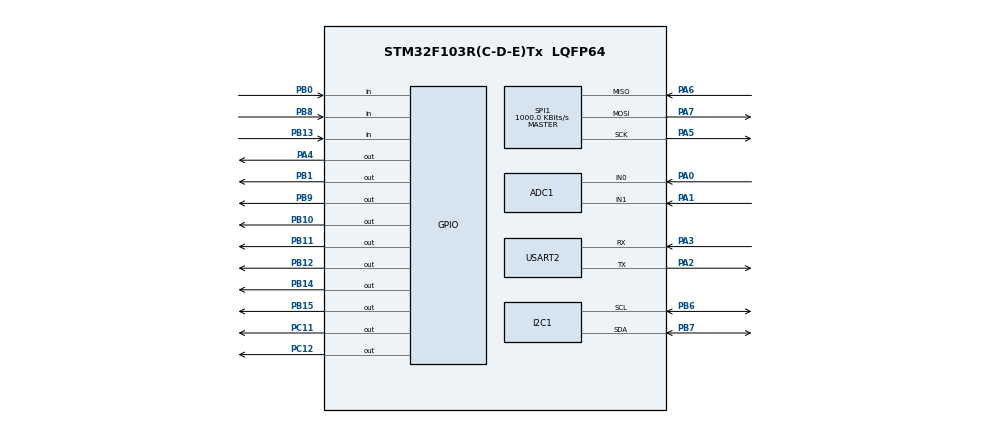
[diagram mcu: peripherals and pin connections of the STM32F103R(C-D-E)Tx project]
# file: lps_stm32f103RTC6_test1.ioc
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ADC1.Channel-0\#ChannelRegularConversion=ADC_CHANNEL_0
ADC1.NbrOfConversionFlag=1
ADC1.Rank-0\#ChannelRegularConversion=1
ADC1.SamplingTime-0\#ChannelRegularConversion=ADC_SAMPLETIME_1CYCLE_5
ADC1.master=1
Mcu.Family=STM32F1
Mcu.Name=STM32F103R(C-D-E)Tx
Mcu.Package=LQFP64
NVIC.PriorityGroup=NVIC_PRIORITYGROUP_4
PA0-WKUP.Signal=ADCx_IN0
PA1.Signal=ADCx_IN1
PA2.Mode=Asynchronous
PA2.Signal=USART2_TX
PA3.Mode=Asynchronous
PA3.Signal=USART2_RX
PA4.Signal=GPIO_Output
PA5.Mode=Full_Duplex_Master
PA5.Signal=SPI1_SCK
PA6.Mode=Full_Duplex_Master
PA6.Signal=SPI1_MISO
PA7.Mode=Full_Duplex_Master
PA7.Signal=SPI1_MOSI
PB0.Signal=GPIO_Input
PB1.Signal=GPIO_Output
PB10.Signal=GPIO_Output
PB11.Signal=GPIO_Output
PB12.Signal=GPIO_Output
PB13.Signal=GPIO_Input
PB14.Signal=GPIO_Output
PB15.Signal=GPIO_Output
PB6.Mode=I2C
PB6.Signal=I2C1_SCL
PB7.Mode=I2C
PB7.Signal=I2C1_SDA
PB8.Signal=GPIO_Input
PB9.Signal=GPIO_Output
PC11.Signal=GPIO_Output
PC12.Signal=GPIO_Output
ProjectManager.HeapSize=0x200
ProjectManager.StackSize=0x400
ProjectManager.TargetToolchain=STM32CubeIDE
RCC.APB1Freq_Value=8000000
RCC.APB2Freq_Value=8000000
SH.ADCx_IN0.0=ADC1_IN0,IN0
SH.ADCx_IN1.0=ADC1_IN1,IN1
SPI1.BaudRatePrescaler=SPI_BAUDRATEPRESCALER_8
SPI1.CLKPhase=SPI_PHASE_2EDGE
SPI1.CLKPolarity=SPI_POLARITY_HIGH
SPI1.CalculateBaudRate=1000.0 KBits/s
SPI1.Direction=SPI_DIRECTION_2LINES
SPI1.Mode=SPI_MODE_MASTER
SPI1.VirtualType=VM_MASTER
USART2.VirtualMode=VM_ASYNC
VP_SYS_VS_ND.Mode=No_Debug
board=custom

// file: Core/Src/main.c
/* USER CODE BEGIN Header */
/**
  ******************************************************************************
  * @file           : main.c
  * @brief          : Main program body
  ******************************************************************************
  * @attention
  *
  * Copyright (c) 2024 STMicroelectronics.
  * All rights reserved.
  *
  * This software is licensed under terms that can be found in the LICENSE file
  * in the root directory of this software component.
  * If no LICENSE file comes with this software, it is provided AS-IS.
  *
  ******************************************************************************
  */
/* USER CODE END Header */
#include "main.h"

/* USER CODE BEGIN Includes */
#include <string.h>
#include <stdio.h>

#include "main_loop.h"

/* USER CODE END Includes */

ADC_HandleTypeDef hadc1;

I2C_HandleTypeDef hi2c1;

SPI_HandleTypeDef hspi1;

UART_HandleTypeDef huart2;

/* USER CODE BEGIN PV */
//static const uint8_t TMP102_ADDR = 0x18 <<1; // Use 8-bit address
//static const uint8_t REG_TEMP = 0x05;

/* USER CODE END PV */

void SystemClock_Config(void);
static void MX_GPIO_Init(void);
static void MX_I2C1_Init(void);
static void MX_USART2_UART_Init(void);
static void MX_SPI1_Init(void);
static void MX_ADC1_Init(void);
/* USER CODE BEGIN PFP */
#define PUTCHAR_PROTOTYPE int __io_putchar(int ch)

/* USER CODE END PFP */

int main(void)
{

  /* MCU Configuration--------------------------------------------------------*/

  /* Reset of all peripherals, Initializes the Flash interface and the Systick. */
  HAL_Init();

  /* Configure the system clock */
  SystemClock_Config();

  /* Initialize all configured peripherals */
  MX_GPIO_Init();
  MX_I2C1_Init();
  MX_USART2_UART_Init();
  MX_SPI1_Init();
  MX_ADC1_Init();

  /* Infinite loop */
  /* USER CODE BEGIN WHILE */

  lps_setup();

  while (1)
  {
	lps_loop();

    /* USER CODE END WHILE */

  }
}

void SystemClock_Config(void)
{
  RCC_OscInitTypeDef RCC_OscInitStruct = {0};
  RCC_ClkInitTypeDef RCC_ClkInitStruct = {0};
  RCC_PeriphCLKInitTypeDef PeriphClkInit = {0};

  /** Initializes the RCC Oscillators according to the specified parameters
  * in the RCC_OscInitTypeDef structure.
  */
  RCC_OscInitStruct.OscillatorType = RCC_OSCILLATORTYPE_HSI;
  RCC_OscInitStruct.HSIState = RCC_HSI_ON;
  RCC_OscInitStruct.HSICalibrationValue = RCC_HSICALIBRATION_DEFAULT;
  RCC_OscInitStruct.PLL.PLLState = RCC_PLL_NONE;
  if (HAL_RCC_OscConfig(&RCC_OscInitStruct) != HAL_OK)
  {
    Error_Handler();
  }

  /** Initializes the CPU, AHB and APB buses clocks
  */
  RCC_ClkInitStruct.ClockType = RCC_CLOCKTYPE_HCLK|RCC_CLOCKTYPE_SYSCLK
                              |RCC_CLOCKTYPE_PCLK1|RCC_CLOCKTYPE_PCLK2;
  RCC_ClkInitStruct.SYSCLKSource = RCC_SYSCLKSOURCE_HSI;
  RCC_ClkInitStruct.AHBCLKDivider = RCC_SYSCLK_DIV1;
  RCC_ClkInitStruct.APB1CLKDivider = RCC_HCLK_DIV1;
  RCC_ClkInitStruct.APB2CLKDivider = RCC_HCLK_DIV1;

  if (HAL_RCC_ClockConfig(&RCC_ClkInitStruct, FLASH_LATENCY_0) != HAL_OK)
  {
    Error_Handler();
  }
  PeriphClkInit.PeriphClockSelection = RCC_PERIPHCLK_ADC;
  PeriphClkInit.AdcClockSelection = RCC_ADCPCLK2_DIV2;
  if (HAL_RCCEx_PeriphCLKConfig(&PeriphClkInit) != HAL_OK)
  {
    Error_Handler();
  }
}

static void MX_ADC1_Init(void)
{

  ADC_ChannelConfTypeDef sConfig = {0};

  /** Common config
  */
  hadc1.Instance = ADC1;
  hadc1.Init.ScanConvMode = ADC_SCAN_DISABLE;
  hadc1.Init.ContinuousConvMode = DISABLE;
  hadc1.Init.DiscontinuousConvMode = DISABLE;
  hadc1.Init.ExternalTrigConv = ADC_SOFTWARE_START;
  hadc1.Init.DataAlign = ADC_DATAALIGN_RIGHT;
  hadc1.Init.NbrOfConversion = 1;
  if (HAL_ADC_Init(&hadc1) != HAL_OK)
  {
    Error_Handler();
  }

  /** Configure Regular Channel
  */
  sConfig.Channel = ADC_CHANNEL_0;
  sConfig.Rank = ADC_REGULAR_RANK_1;
  sConfig.SamplingTime = ADC_SAMPLETIME_1CYCLE_5;
  if (HAL_ADC_ConfigChannel(&hadc1, &sConfig) != HAL_OK)
  {
    Error_Handler();
  }

}

static void MX_I2C1_Init(void)
{

  hi2c1.Instance = I2C1;
  hi2c1.Init.ClockSpeed = 100000;
  hi2c1.Init.DutyCycle = I2C_DUTYCYCLE_2;
  hi2c1.Init.OwnAddress1 = 0;
  hi2c1.Init.AddressingMode = I2C_ADDRESSINGMODE_7BIT;
  hi2c1.Init.DualAddressMode = I2C_DUALADDRESS_DISABLE;
  hi2c1.Init.OwnAddress2 = 0;
  hi2c1.Init.GeneralCallMode = I2C_GENERALCALL_DISABLE;
  hi2c1.Init.NoStretchMode = I2C_NOSTRETCH_DISABLE;
  if (HAL_I2C_Init(&hi2c1) != HAL_OK)
  {
    Error_Handler();
  }

}

static void MX_SPI1_Init(void)
{

  /* SPI1 parameter configuration*/
  hspi1.Instance = SPI1;
  hspi1.Init.Mode = SPI_MODE_MASTER;
  hspi1.Init.Direction = SPI_DIRECTION_2LINES;
  hspi1.Init.DataSize = SPI_DATASIZE_8BIT;
  hspi1.Init.CLKPolarity = SPI_POLARITY_HIGH;
  hspi1.Init.CLKPhase = SPI_PHASE_2EDGE;
  hspi1.Init.NSS = SPI_NSS_SOFT;
  hspi1.Init.BaudRatePrescaler = SPI_BAUDRATEPRESCALER_2; // 8;
  hspi1.Init.FirstBit = SPI_FIRSTBIT_MSB;
  hspi1.Init.TIMode = SPI_TIMODE_DISABLE;
  hspi1.Init.CRCCalculation = SPI_CRCCALCULATION_DISABLE;
  hspi1.Init.CRCPolynomial = 10;
  if (HAL_SPI_Init(&hspi1) != HAL_OK)
  {
    Error_Handler();
  }

}

static void MX_USART2_UART_Init(void)
{

  huart2.Instance = USART2;
  huart2.Init.BaudRate = 115200;
  huart2.Init.WordLength = UART_WORDLENGTH_8B;
  huart2.Init.StopBits = UART_STOPBITS_1;
  huart2.Init.Parity = UART_PARITY_NONE;
  huart2.Init.Mode = UART_MODE_TX_RX;
  huart2.Init.HwFlowCtl = UART_HWCONTROL_NONE;
  huart2.Init.OverSampling = UART_OVERSAMPLING_16;
  if (HAL_UART_Init(&huart2) != HAL_OK)
  {
    Error_Handler();
  }

}

static void MX_GPIO_Init(void)
{
  GPIO_InitTypeDef GPIO_InitStruct = {0};

  /* GPIO Ports Clock Enable */
  __HAL_RCC_GPIOA_CLK_ENABLE();
  __HAL_RCC_GPIOB_CLK_ENABLE();
  __HAL_RCC_GPIOC_CLK_ENABLE();

  /*Configure GPIO pin Output Level */
  HAL_GPIO_WritePin(GPIOA, GPIO_PIN_4, GPIO_PIN_RESET);

  /*Configure GPIO pin Output Level */
  HAL_GPIO_WritePin(GPIOB, GPIO_PIN_1|GPIO_PIN_10|GPIO_PIN_11|GPIO_PIN_12
                          |GPIO_PIN_14|GPIO_PIN_15|GPIO_PIN_9, GPIO_PIN_RESET);

  /*Configure GPIO pin Output Level */
  HAL_GPIO_WritePin(GPIOC, GPIO_PIN_11|GPIO_PIN_12, GPIO_PIN_RESET);

  /*Configure GPIO pin : PA4 */
  GPIO_InitStruct.Pin = GPIO_PIN_4;
  GPIO_InitStruct.Mode = GPIO_MODE_OUTPUT_PP;
  GPIO_InitStruct.Pull = GPIO_NOPULL;
  GPIO_InitStruct.Speed = GPIO_SPEED_FREQ_LOW;
  HAL_GPIO_Init(GPIOA, &GPIO_InitStruct);

  /*Configure GPIO pins : PB0 PB13 PB8 */
  GPIO_InitStruct.Pin = GPIO_PIN_0|GPIO_PIN_13|GPIO_PIN_8;
  GPIO_InitStruct.Mode = GPIO_MODE_INPUT;
  GPIO_InitStruct.Pull = GPIO_NOPULL;
  HAL_GPIO_Init(GPIOB, &GPIO_InitStruct);

  /*Configure GPIO pins : PB1 PB10 PB11 PB12
                           PB14 PB15 PB9 */
  GPIO_InitStruct.Pin = GPIO_PIN_1|GPIO_PIN_10|GPIO_PIN_11|GPIO_PIN_12
                          |GPIO_PIN_14|GPIO_PIN_15|GPIO_PIN_9;
  GPIO_InitStruct.Mode = GPIO_MODE_OUTPUT_PP;
  GPIO_InitStruct.Pull = GPIO_NOPULL;
  GPIO_InitStruct.Speed = GPIO_SPEED_FREQ_LOW;
  HAL_GPIO_Init(GPIOB, &GPIO_InitStruct);

  /*Configure GPIO pins : PC11 PC12 */
  GPIO_InitStruct.Pin = GPIO_PIN_11|GPIO_PIN_12;
  GPIO_InitStruct.Mode = GPIO_MODE_OUTPUT_PP;
  GPIO_InitStruct.Pull = GPIO_NOPULL;
  GPIO_InitStruct.Speed = GPIO_SPEED_FREQ_LOW;
  HAL_GPIO_Init(GPIOC, &GPIO_InitStruct);

}

/* USER CODE BEGIN 4 */
// https://community.st.com/t5/stm32-mcus-products/how-to-setup-printf-to-print-message-to-console/td-p/174337
/**
  * @brief  Retargets the C library printf function to the USART.
  * @param  None
  * @retval None
  */
PUTCHAR_PROTOTYPE
{
  /* Place your implementation of fputc here */
  /* e.g. write a character to the USART1 and Loop until the end of transmission */
  HAL_UART_Transmit(&huart2, (uint8_t *)&ch, 1, 0xFFFF);

  return ch;
}
/* USER CODE END 4 */

void Error_Handler(void)
{
  __disable_irq();
  while (1)
  {
  }
}
